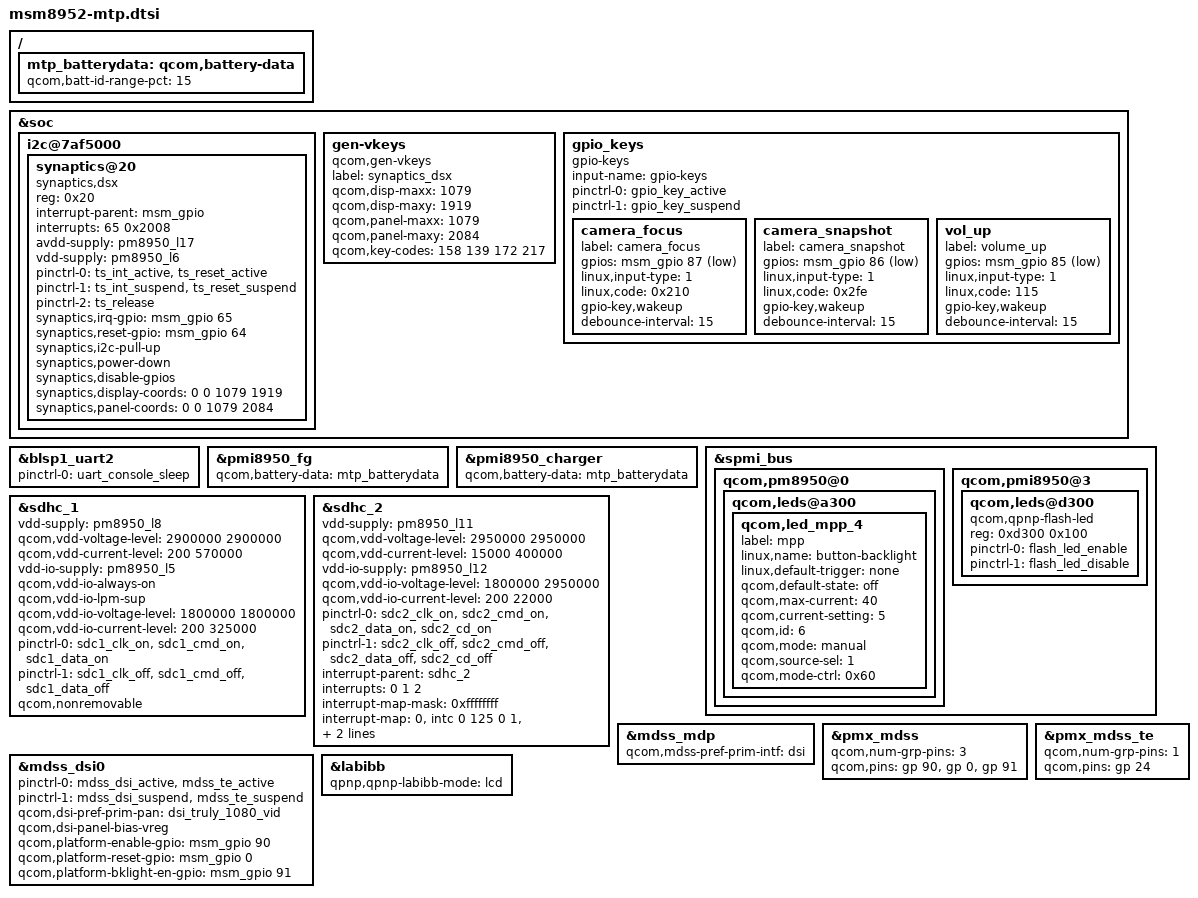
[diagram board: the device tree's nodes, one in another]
/*
 * Copyright (c) 2015, The Linux Foundation. All rights reserved.
 *
 * This program is free software; you can redistribute it and/or modify
 * it under the terms of the GNU General Public License version 2 and
 * only version 2 as published by the Free Software Foundation.
 *
 * This program is distributed in the hope that it will be useful,
 * but WITHOUT ANY WARRANTY; without even the implied warranty of
 * MERCHANTABILITY or FITNESS FOR A PARTICULAR PURPOSE.  See the
 * GNU General Public License for more details.
 */

#include "msm8952.dtsi"
#include "msm8952-pinctrl.dtsi"
#include "msm8952-camera-sensor-mtp.dtsi"

&soc {
	i2c@7af5000 { /* BLSP2 QUP1 */
		synaptics@20 {
			compatible = "synaptics,dsx";
			reg = <0x20>;
			interrupt-parent = <&msm_gpio>;
			interrupts = <65 0x2008>;
			avdd-supply = <&pm8950_l17>;
			vdd-supply = <&pm8950_l6>;
			/* pins used by touchscreen */
			pinctrl-names = "pmx_ts_active","pmx_ts_suspend","pmx_ts_release";
			pinctrl-0 = <&ts_int_active &ts_reset_active>;
			pinctrl-1 = <&ts_int_suspend &ts_reset_suspend>;
			pinctrl-2 = <&ts_release>;
			synaptics,irq-gpio = <&msm_gpio 65 0x2008>;
			synaptics,reset-gpio = <&msm_gpio 64 0x0>;
			synaptics,i2c-pull-up;
			synaptics,power-down;
			synaptics,disable-gpios;
			synaptics,display-coords = <0 0 1079 1919>;
			synaptics,panel-coords = <0 0 1079 2084>;
		};
	};

	gen-vkeys {
		compatible = "qcom,gen-vkeys";
		label = "synaptics_dsx";
		qcom,disp-maxx = <1079>;
		qcom,disp-maxy = <1919>;
		qcom,panel-maxx = <1079>;
		qcom,panel-maxy = <2084>;
		qcom,key-codes = <158 139 172 217>;
	};

	gpio_keys {
		compatible = "gpio-keys";
		input-name = "gpio-keys";
		pinctrl-names = "tlmm_gpio_key_active","tlmm_gpio_key_suspend";
		pinctrl-0 = <&gpio_key_active>;
		pinctrl-1 = <&gpio_key_suspend>;

		camera_focus {
			label = "camera_focus";
			gpios = <&msm_gpio 87 0x1>;
			linux,input-type = <1>;
			linux,code = <0x210>;
			gpio-key,wakeup;
			debounce-interval = <15>;
		};

		camera_snapshot {
			label = "camera_snapshot";
			gpios = <&msm_gpio 86 0x1>;
			linux,input-type = <1>;
			linux,code = <0x2fe>;
			gpio-key,wakeup;
			debounce-interval = <15>;
		};

		vol_up {
			label = "volume_up";
			gpios = <&msm_gpio 85 0x1>;
			linux,input-type = <1>;
			linux,code = <115>;
			gpio-key,wakeup;
			debounce-interval = <15>;
		};
	};
};

&blsp1_uart2 {
	status = "ok";
	pinctrl-names = "default";
	pinctrl-0 = <&uart_console_sleep>;
};

/{
	mtp_batterydata: qcom,battery-data {
		qcom,batt-id-range-pct = <15>;
		#include "batterydata-itech-3000mah-4200mv.dtsi"
		#include "batterydata-itech-3000mah.dtsi"
	};
};

&pmi8950_fg {
	qcom,battery-data = <&mtp_batterydata>;
};

&pmi8950_charger {
	qcom,battery-data = <&mtp_batterydata>;
};

&spmi_bus {
	qcom,pm8950@0 {
		qcom,leds@a300 {
			status = "okay";
			qcom,led_mpp_4 {
				label = "mpp";
				linux,name = "button-backlight";
				linux,default-trigger = "none";
				qcom,default-state = "off";
				qcom,max-current = <40>;
				qcom,current-setting = <5>;
				qcom,id = <6>;
				qcom,mode = "manual";
				qcom,source-sel = <1>;
				qcom,mode-ctrl = <0x60>;
			};
		};
	};

	qcom,pmi8950@3 {
		qcom,leds@d300 {
			compatible = "qcom,qpnp-flash-led";
			status = "okay";
			reg = <0xd300 0x100>;
			pinctrl-names = "flash_led_enable","flash_led_disable";
			pinctrl-0 = <&flash_led_enable>;
			pinctrl-1 = <&flash_led_disable>;
		};
	};
};

&sdhc_1 {
	vdd-supply = <&pm8950_l8>;
	qcom,vdd-voltage-level = <2900000 2900000>;
	qcom,vdd-current-level = <200 570000>;

	vdd-io-supply = <&pm8950_l5>;
	qcom,vdd-io-always-on;
	qcom,vdd-io-lpm-sup;
	qcom,vdd-io-voltage-level = <1800000 1800000>;
	qcom,vdd-io-current-level = <200 325000>;

	pinctrl-names = "active", "sleep";
	pinctrl-0 = <&sdc1_clk_on &sdc1_cmd_on &sdc1_data_on>;
	pinctrl-1 = <&sdc1_clk_off &sdc1_cmd_off &sdc1_data_off>;

	qcom,nonremovable;

	status = "ok";
};

&sdhc_2 {
	vdd-supply = <&pm8950_l11>;
	qcom,vdd-voltage-level = <2950000 2950000>;
	qcom,vdd-current-level = <15000 400000>;

	vdd-io-supply = <&pm8950_l12>;
	qcom,vdd-io-voltage-level = <1800000 2950000>;
	qcom,vdd-io-current-level = <200 22000>;

	pinctrl-names = "active", "sleep";
	pinctrl-0 = <&sdc2_clk_on &sdc2_cmd_on &sdc2_data_on &sdc2_cd_on>;
	pinctrl-1 = <&sdc2_clk_off &sdc2_cmd_off &sdc2_data_off &sdc2_cd_off>;

	#address-cells = <0>;
	interrupt-parent = <&sdhc_2>;
	interrupts = <0 1 2>;
	#interrupt-cells = <1>;
	interrupt-map-mask = <0xffffffff>;
	interrupt-map = <0 &intc 0 125 0
			1 &intc 0 221 0
			2 &msm_gpio 67 0>;
	interrupt-names = "hc_irq", "pwr_irq", "status_irq";
	cd-gpios = <&msm_gpio 67 0x1>;

	status = "ok";
};

#include "dsi-panel-truly-1080p-video.dtsi"

&mdss_mdp {
	qcom,mdss-pref-prim-intf = "dsi";
};

&pmx_mdss {
	qcom,num-grp-pins = <3>;
	qcom,pins = <&gp 90>, <&gp 0>, <&gp 91>;
};

&pmx_mdss_te {
	qcom,num-grp-pins = <1>;
	qcom,pins = <&gp 24>;
};

&mdss_dsi0 {
	pinctrl-names = "mdss_default", "mdss_sleep";
	pinctrl-0 = <&mdss_dsi_active &mdss_te_active>;
	pinctrl-1 = <&mdss_dsi_suspend &mdss_te_suspend>;
	qcom,dsi-pref-prim-pan = <&dsi_truly_1080_vid>;
	qcom,dsi-panel-bias-vreg;

	qcom,platform-enable-gpio = <&msm_gpio 90 0>;
	qcom,platform-reset-gpio = <&msm_gpio 0 0>;
	qcom,platform-bklight-en-gpio = <&msm_gpio 91 0>;
};

&labibb {
	status = "ok";
	qpnp,qpnp-labibb-mode = "lcd";
};
